# MCAN0_ECC_AGGR register map
Vendor: Texas Instruments
Peripheral module from a debugger description file (folder J7VCL).
Registers are 32-bit, access not given, reset 0x0 unless marked. A register's access mark holds for its fields unless they carry their own. Offsets are as the file gives them; lines under a group give offsets from that group; [hi:lo] are bit positions; {n}, {i} and the like mark numbered series; 'fields as' and 'values as' point back to an identical list; <NAME> marks a mode.

## MCAN0_ECC_AGGR
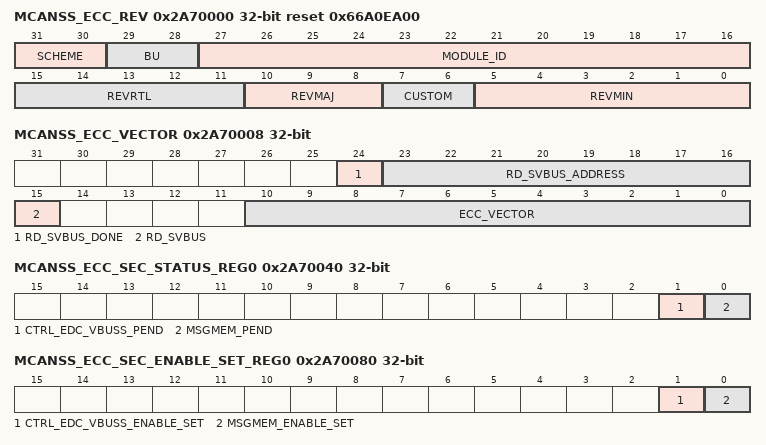
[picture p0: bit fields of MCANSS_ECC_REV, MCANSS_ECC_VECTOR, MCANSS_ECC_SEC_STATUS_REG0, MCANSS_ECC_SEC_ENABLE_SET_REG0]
0x2A70000 MCANSS_ECC_REV ro reset 0x66A0EA00 — Aggregator Revision Register The Aggregator Revision Register contains the revision parameters for the ECC Aggregator.
  [31:30] SCHEME
  [29:28] BU — Business Unit
  [27:16] MODULE_ID
  [15:11] REVRTL — RTL Version
  [10:8] REVMAJ — Major Version
  [7:6] CUSTOM — Custom Version
  [5:0] REVMIN — Minor Version
0x2A70008 MCANSS_ECC_VECTOR — ECC Vector Register
  [24] RD_SVBUS_DONE — Read Done Status to indicate if read on the serial ECC interface is complete, write of any value will clear this bit. (access RW1C)
  [23:16] RD_SVBUS_ADDRESS rw — Read Address
  [15] RD_SVBUS — Read Trigger Write 1h to trigger a read on the serial ECC interface. (access RW1S)
  [10:0] ECC_VECTOR rw — ECC RAM ID Value written to select the corresponding ECC RAM for control or status.
0x2A7000C MCANSS_ECC_STAT ro reset 0x2 — Misc Status Register
  [10:0] NUM_RAMS — Number of RAMs Indicates the number of RAMs serviced by the ECC Aggregator.
0x2A7003C MCANSS_ECC_SEC_EOI_REG — SEC EOI Register The EOI register is used to re-trigger the pulse interrupt signal to ensure that any nested interrupt events are serviced. The software interrupt handler must write to the EOI register at the end of the current interrupt processing routine, so that new events can re-trigger the pulse interrupt signal again. For level interrupt signals the EOI register is not functional and must not be used.
  [0] EOI_WR — Single Error Correction End Of Interrupt (SEC EOI) (access RW1S)
0x2A70040 MCANSS_ECC_SEC_STATUS_REG0 — SEC Interrupt Status Register 0
  [1] CTRL_EDC_VBUSS_PEND — Interrupt Pending Status for CTRL_EDC_VBUSS_PEND (access RW1S)
  [0] MSGMEM_PEND — Interrupt Pending Status for MSGMEM_PEND (access RW1S)
0x2A70080 MCANSS_ECC_SEC_ENABLE_SET_REG0 — SEC Interrupt Enable Set Register 0
  [1] CTRL_EDC_VBUSS_ENABLE_SET — Interrupt Enable Set for CTRL_EDC_VBUSS_PEND (access RW1S)
  [0] MSGMEM_ENABLE_SET — Interrupt Enable Set for MSGMEM_PEND (access RW1S)
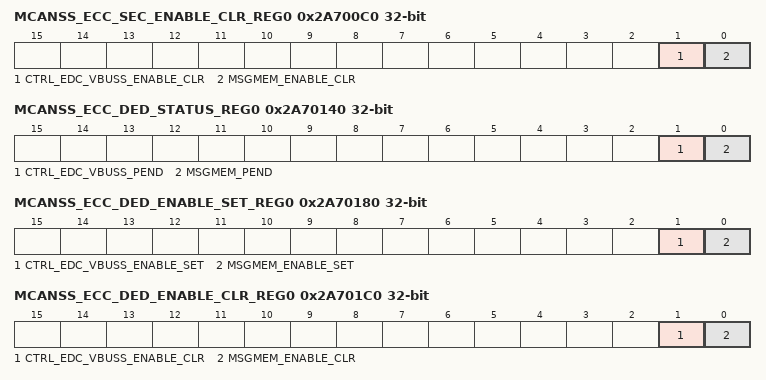
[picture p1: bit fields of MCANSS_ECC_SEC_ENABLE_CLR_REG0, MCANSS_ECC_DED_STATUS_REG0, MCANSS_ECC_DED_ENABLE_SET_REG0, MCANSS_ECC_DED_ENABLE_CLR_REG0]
0x2A700C0 MCANSS_ECC_SEC_ENABLE_CLR_REG0 — SEC Interrupt Enable Clear Register 0
  [1] CTRL_EDC_VBUSS_ENABLE_CLR — Interrupt Enable Clear for CTRL_EDC_VBUSS_PEND (access RW1C)
  [0] MSGMEM_ENABLE_CLR — Interrupt Enable Clear for MSGMEM_PEND (access RW1C)
0x2A7013C MCANSS_ECC_DED_EOI_REG — DED EOI Register The EOI register is used to re-trigger the pulse interrupt signal to ensure that any nested interrupt events are serviced. The software interrupt handler must write to the EOI register at the end of the current interrupt processing routine, so that new events can re-trigger the pulse interrupt signal again. For level interrupt signals the EOI register is not functional and must not be used.
  [0] EOI_WR — Double Error Correction End Of Interrupt (DED EOI) (access RW1S)
0x2A70140 MCANSS_ECC_DED_STATUS_REG0 — DED Interrupt Status Register 0
  fields as MCANSS_ECC_SEC_STATUS_REG0
0x2A70180 MCANSS_ECC_DED_ENABLE_SET_REG0 — DED Interrupt Enable Set Register 0
  fields as MCANSS_ECC_SEC_ENABLE_SET_REG0
0x2A701C0 MCANSS_ECC_DED_ENABLE_CLR_REG0 — DED Interrupt Enable Clear Register 0
  fields as MCANSS_ECC_SEC_ENABLE_CLR_REG0
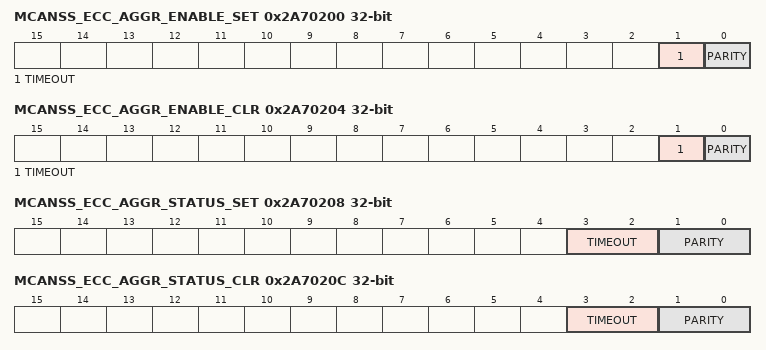
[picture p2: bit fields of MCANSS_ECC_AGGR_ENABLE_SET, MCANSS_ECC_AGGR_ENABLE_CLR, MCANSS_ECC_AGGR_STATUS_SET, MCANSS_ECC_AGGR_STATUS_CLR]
0x2A70200 MCANSS_ECC_AGGR_ENABLE_SET — Aggregator Interrupt Enable Set Register
  [1] TIMEOUT — Interrupt Enable Set for Serial ECC Interface Timeout Errors (access RW1S)
  [0] PARITY — Interrupt Enable Set for Parity Errors (access RW1S)
0x2A70204 MCANSS_ECC_AGGR_ENABLE_CLR — Aggregator Interrupt Enable Clear Register
  [1] TIMEOUT — Interrupt Enable Clear for Serial ECC Interface Timeout Errors (access RW1C)
  [0] PARITY — Interrupt Enable Clear for Parity Errors (access RW1C)
0x2A70208 MCANSS_ECC_AGGR_STATUS_SET — Aggregator Interrupt Status Set Register
  [3:2] TIMEOUT — Interrupt Status Set for Serial ECC Interface Timeout Errors (access RWincr)
  [1:0] PARITY — Interrupt Status Set for Parity Errors (access RWincr)
0x2A7020C MCANSS_ECC_AGGR_STATUS_CLR — Aggregator Interrupt Status Clear Register
  [3:2] TIMEOUT — Interrupt Status Clear for Serial ECC Interface Timeout Errors (access RWdecr)
  [1:0] PARITY — Interrupt Status Clear for Parity Errors (access RWdecr)
